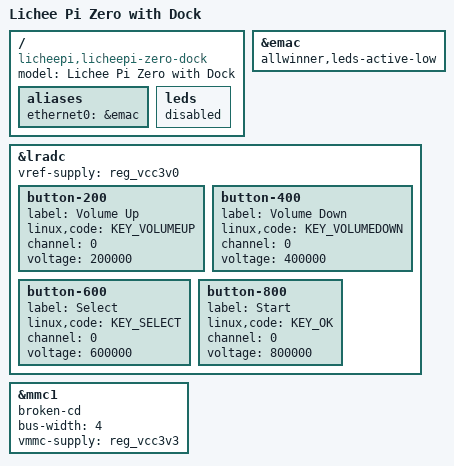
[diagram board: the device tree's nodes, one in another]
/*
 * Copyright (C) 2016 Icenowy Zheng <icenowy@aosc.xyz>
 *
 * This file is dual-licensed: you can use it either under the terms
 * of the GPL or the X11 license, at your option. Note that this dual
 * licensing only applies to this file, and not this project as a
 * whole.
 *
 *  a) This file is free software; you can redistribute it and/or
 *     modify it under the terms of the GNU General Public License as
 *     published by the Free Software Foundation; either version 2 of the
 *     License, or (at your option) any later version.
 *
 *     This file is distributed in the hope that it will be useful,
 *     but WITHOUT ANY WARRANTY; without even the implied warranty of
 *     MERCHANTABILITY or FITNESS FOR A PARTICULAR PURPOSE.  See the
 *     GNU General Public License for more details.
 *
 * Or, alternatively,
 *
 *  b) Permission is hereby granted, free of charge, to any person
 *     obtaining a copy of this software and associated documentation
 *     files (the "Software"), to deal in the Software without
 *     restriction, including without limitation the rights to use,
 *     copy, modify, merge, publish, distribute, sublicense, and/or
 *     sell copies of the Software, and to permit persons to whom the
 *     Software is furnished to do so, subject to the following
 *     conditions:
 *
 *     The above copyright notice and this permission notice shall be
 *     included in all copies or substantial portions of the Software.
 *
 *     THE SOFTWARE IS PROVIDED "AS IS", WITHOUT WARRANTY OF ANY KIND,
 *     EXPRESS OR IMPLIED, INCLUDING BUT NOT LIMITED TO THE WARRANTIES
 *     OF MERCHANTABILITY, FITNESS FOR A PARTICULAR PURPOSE AND
 *     NONINFRINGEMENT. IN NO EVENT SHALL THE AUTHORS OR COPYRIGHT
 *     HOLDERS BE LIABLE FOR ANY CLAIM, DAMAGES OR OTHER LIABILITY,
 *     WHETHER IN AN ACTION OF CONTRACT, TORT OR OTHERWISE, ARISING
 *     FROM, OUT OF OR IN CONNECTION WITH THE SOFTWARE OR THE USE OR
 *     OTHER DEALINGS IN THE SOFTWARE.
 */

#include "sun8i-v3s-licheepi-zero.dts"

#include <dt-bindings/input/input.h>

/ {
	model = "Lichee Pi Zero with Dock";
	compatible = "licheepi,licheepi-zero-dock", "licheepi,licheepi-zero",
		     "allwinner,sun8i-v3s";

	aliases {
		ethernet0 = &emac;
	};

	leds {
		/* The LEDs use PG0~2 pins, which conflict with MMC1 */
		status = "disabled";
	};
};

&emac {
	allwinner,leds-active-low;
	status = "okay";
};

&lradc {
	vref-supply = <&reg_vcc3v0>;
	status = "okay";

	button-200 {
		label = "Volume Up";
		linux,code = <KEY_VOLUMEUP>;
		channel = <0>;
		voltage = <200000>;
	};

	button-400 {
		label = "Volume Down";
		linux,code = <KEY_VOLUMEDOWN>;
		channel = <0>;
		voltage = <400000>;
	};

	button-600 {
		label = "Select";
		linux,code = <KEY_SELECT>;
		channel = <0>;
		voltage = <600000>;
	};

	button-800 {
		label = "Start";
		linux,code = <KEY_OK>;
		channel = <0>;
		voltage = <800000>;
	};
};

&mmc1 {
	broken-cd;
	bus-width = <4>;
	vmmc-supply = <&reg_vcc3v3>;
	status = "okay";
};
